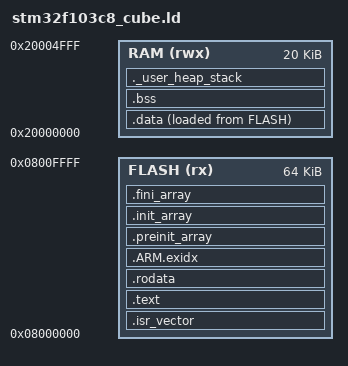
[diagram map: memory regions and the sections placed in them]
/* Copyright (c) 2026 Ricardo Kerschbaumer; SPDX-License-Identifier: MIT */
/* STM32F103C8 layout for firmware that uses ST's startup file and newlib-nano,
   like an STM32CubeIDE project: the symbols the startup file and the C library
   expect (_estack, _sidata, _sdata, _edata, _sbss, _ebss, end). */
ENTRY(Reset_Handler)
MEMORY {
    FLASH (rx) : ORIGIN = 0x08000000, LENGTH = 64K
    RAM (rwx) : ORIGIN = 0x20000000, LENGTH = 20K
}
_estack = ORIGIN(RAM) + LENGTH(RAM);
_Min_Heap_Size = 0x200;
_Min_Stack_Size = 0x400;
SECTIONS {
    .isr_vector : { . = ALIGN(4); KEEP(*(.isr_vector)) . = ALIGN(4); } > FLASH
    .text : {
        . = ALIGN(4);
        *(.text*) *(.glue_7) *(.glue_7t) *(.eh_frame)
        KEEP(*(.init)) KEEP(*(.fini))
        . = ALIGN(4);
    } > FLASH
    .rodata : { . = ALIGN(4); *(.rodata*) . = ALIGN(4); } > FLASH
    .ARM.exidx : { *(.ARM.exidx* .gnu.linkonce.armexidx.*) } > FLASH
    .preinit_array : {
        PROVIDE_HIDDEN(__preinit_array_start = .);
        KEEP(*(.preinit_array*))
        PROVIDE_HIDDEN(__preinit_array_end = .);
    } > FLASH
    .init_array : {
        PROVIDE_HIDDEN(__init_array_start = .);
        KEEP(*(SORT(.init_array.*))) KEEP(*(.init_array*))
        PROVIDE_HIDDEN(__init_array_end = .);
    } > FLASH
    .fini_array : {
        PROVIDE_HIDDEN(__fini_array_start = .);
        KEEP(*(SORT(.fini_array.*))) KEEP(*(.fini_array*))
        PROVIDE_HIDDEN(__fini_array_end = .);
    } > FLASH
    _sidata = LOADADDR(.data);
    .data : {
        . = ALIGN(4);
        _sdata = .;
        *(.data*)
        . = ALIGN(4);
        _edata = .;
    } > RAM AT> FLASH
    .bss (NOLOAD) : {
        . = ALIGN(4);
        _sbss = .;
        __bss_start__ = _sbss;
        *(.bss*) *(COMMON)
        . = ALIGN(4);
        _ebss = .;
        __bss_end__ = _ebss;
    } > RAM
    ._user_heap_stack (NOLOAD) : {
        . = ALIGN(8);
        PROVIDE(end = .);
        PROVIDE(_end = .);
        . = . + _Min_Heap_Size;
        . = . + _Min_Stack_Size;
        . = ALIGN(8);
    } > RAM
    /DISCARD/ : { libc.a(*) libm.a(*) libgcc.a(*) }
    .ARM.attributes 0 : { *(.ARM.attributes) }
}
